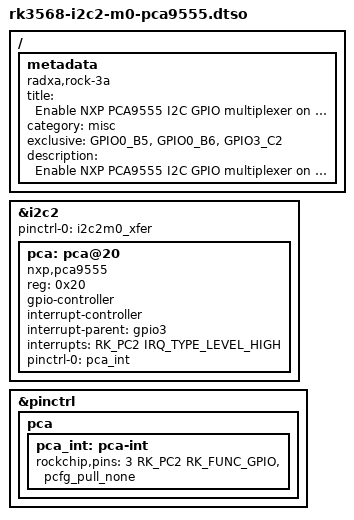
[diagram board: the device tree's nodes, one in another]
/dts-v1/;
/plugin/;

#include <dt-bindings/gpio/gpio.h>
#include <dt-bindings/pinctrl/rockchip.h>
#include <dt-bindings/interrupt-controller/irq.h>

/{
	metadata {
		title = "Enable NXP PCA9555 I2C GPIO multiplexer on I2C2-M0";
		compatible = "radxa,rock-3a", "radxa,rock-3b";
		category = "misc";
		exclusive = "GPIO0_B5", "GPIO0_B6", "GPIO3_C2";
		description = "Enable NXP PCA9555 I2C GPIO multiplexer on I2C2-M0.
On Radxa ROCK-3A and ROCK-3B pin 07 is I2C_SCL, pin 16 is I2C_SDA, pin 32 is interrupt pin(optional).";
	};
};

&i2c2 {
	status = "okay";
	#address-cells = <1>;
	#size-cells = <0>;
	pinctrl-names = "default";
	pinctrl-0 = <&i2c2m0_xfer>;

	pca: pca@20 {
		compatible = "nxp,pca9555";
		reg = <0x20>;
		gpio-controller;
		#gpio-cells = <2>;
		interrupt-controller;
		#interrupt-cells = <2>;
		interrupt-parent = <&gpio3>;
		interrupts = <RK_PC2 IRQ_TYPE_LEVEL_HIGH>;
		pinctrl-names = "default";
		pinctrl-0 = <&pca_int>;
		status = "okay";
	};
};

&pinctrl {
	pca {
		pca_int: pca-int {
			rockchip,pins = <3 RK_PC2 RK_FUNC_GPIO &pcfg_pull_none>;
		};
	};
};
